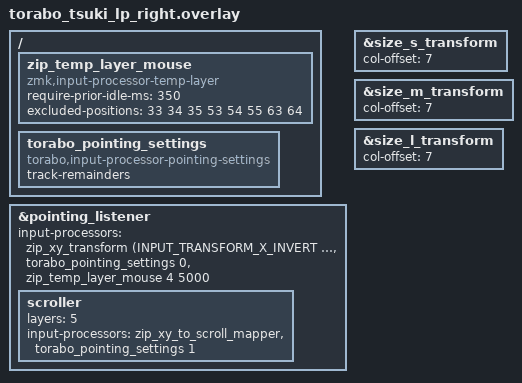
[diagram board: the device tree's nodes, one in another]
#include "torabo_tsuki_lp.dtsi"
#include <input/processors.dtsi>
#include <dt-bindings/zmk/input_transform.h>

/ {
    zip_temp_layer_mouse: zip_temp_layer_mouse {
        compatible = "zmk,input-processor-temp-layer";
        #input-processor-cells = <2>;
        require-prior-idle-ms = <350>;
        /* Mouse buttons and modifiers stay available for modified clicks. */
        excluded-positions = <33 34 35 53 54 55 63 64>;
    };

    torabo_pointing_settings: torabo_pointing_settings {
        compatible = "torabo,input-processor-pointing-settings";
        #input-processor-cells = <1>;
        track-remainders;
    };
};

&pointing_listener {
    input-processors =
        <&zip_xy_transform (INPUT_TRANSFORM_X_INVERT | INPUT_TRANSFORM_Y_INVERT)>,
        <&torabo_pointing_settings 0>,
        <&zip_temp_layer_mouse 4 5000>;

    scroller {
        layers = <5>;
        input-processors =
            <&zip_xy_to_scroll_mapper>,
            <&torabo_pointing_settings 1>;
    };
};

&size_s_transform {
    col-offset = <7>;
};

&size_m_transform {
    col-offset = <7>;
};

&size_l_transform {
    col-offset = <7>;
};
